# GD32G5x3 register map
File version: 1.0
CPU: CM33 r2p1, little endian, MPU, FPU, 4 interrupt priority bits
Registers are 32-bit, read-write, reset 0x0 unless marked. A register's access mark holds for its fields unless they carry their own. Offsets are from the block's base; [hi:lo] are bit positions.

## DAC0 — Digital-to-analog converter
Base 0x50001000
Same registers: DAC1 0x50001400, DAC2 0x50001800, DAC3 0x50001C00
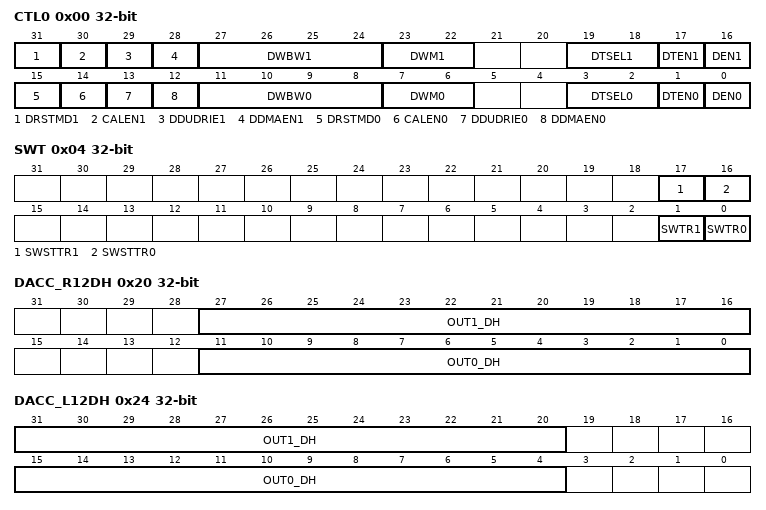
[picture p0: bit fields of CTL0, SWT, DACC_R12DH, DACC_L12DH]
0x00 CTL0 — Control register 0
  [31] DRSTMD1 — DAC_OUT1 reset mode
  [30] CALEN1 — DAC_OUT1 calibration enable
  [29] DDUDRIE1 — DAC_OUT1 DMA underrun interrupt enable
  [28] DDMAEN1 — DAC_OUT1 DMA enable
  [27:24] DWBW1 — DAC_OUT1 noise wave bit width
  [23:22] DWM1 — DAC_OUT1 noise wave mode
  [19:18] DTSEL1 — DAC_OUT1 trigger selection
  [17] DTEN1 — DAC_OUT1 trigger enable
  [16] DEN1 — DAC_OUT1 enable
  [15] DRSTMD0 — DAC_OUT0 reset mode
  [14] CALEN0 — DAC_OUT0 calibration enable
  [13] DDUDRIE0 — DAC_OUT0 DMA underrun interrupt enable
  [12] DDMAEN0 — DAC_OUT0 DMA enable
  [11:8] DWBW0 — DAC_OUT0 noise wave bit width
  [7:6] DWM0 — DAC_OUT0 noise wave mode
  [3:2] DTSEL0 — DAC_OUT0 trigger selection
  [1] DTEN0 — DAC_OUT0 trigger enable
  [0] DEN0 — DAC_OUT0 enable
0x04 SWT wo — Software trigger register
  [17] SWSTTR1 — DAC_OUT1 sawtooth step-up/down software trigger
  [16] SWSTTR0 — DAC_OUT0 sawtooth step-up/down software trigger
  [1] SWTR1 — DAC_OUT1 software trigger, cleared by hardware
  [0] SWTR0 — DAC_OUT0 software trigger, cleared by hardware
0x08 OUT0_R12DH — DAC_OUT0 12-bit right-aligned data holding register
  [11:0] OUT0_DH — DAC_OUT0 12-bit right-aligned data
0x0C OUT0_L12DH — DAC_OUT0 12-bit left-aligned data holding register
  [15:4] OUT0_DH — DAC_OUT0 12-bit left-aligned data
0x10 OUT0_R8DH — DAC_OUT0 8-bit right-aligned data holding register
  [7:0] OUT0_DH — DAC_OUT0 8-bit right-aligned data
0x14 OUT1_R12DH — DAC_OUT1 12-bit right-aligned data holding register
  [11:0] OUT1_DH — DAC_OUT1 12-bit right-aligned data
0x18 OUT1_L12DH — DAC_OUT1 12-bit left-aligned data holding register
  [15:4] OUT1_DH — DAC_OUT1 12-bit left-aligned data
0x1C OUT1_R8DH — DAC_OUT1 8-bit right-aligned data holding register
  [7:0] OUT1_DH — DAC_OUT1 8-bit right-aligned data
0x20 DACC_R12DH — DAC concurrent mode 12-bit right-aligned data holding register
  [27:16] OUT1_DH — DAC_OUT1 12-bit right-aligned data
  [11:0] OUT0_DH — DAC_OUT0 12-bit right-aligned data
0x24 DACC_L12DH — DAC concurrent mode 12-bit left-aligned data holding register
  [31:20] OUT1_DH — DAC_OUT1 12-bit left-aligned data
  [15:4] OUT0_DH — DAC_OUT0 12-bit left-aligned data
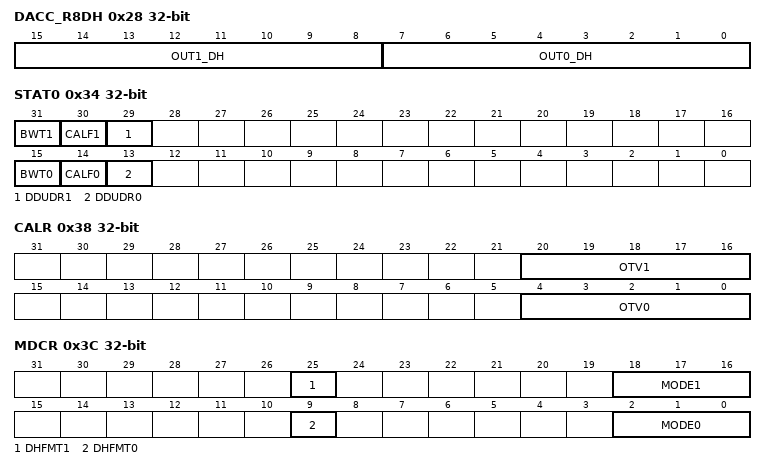
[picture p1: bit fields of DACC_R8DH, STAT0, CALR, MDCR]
0x28 DACC_R8DH — DAC concurrent mode 8-bit right-aligned data holding register
  [15:8] OUT1_DH — DAC_OUT1 8-bit right-aligned data
  [7:0] OUT0_DH — DAC_OUT0 8-bit right-aligned data
0x2C OUT0_DO ro — DAC_OUT0 data output register
  [11:0] OUT0_DO — DAC_OUT0 data output
0x30 OUT1_DO ro — DAC_OUT1 data output register
  [11:0] OUT1_DO — DAC_OUT1 data output
0x34 STAT0 access per field — DAC status register 0
  [31] BWT1 ro — DAC_OUT1 TSAMP1[9:0] writing busy flag
  [30] CALF1 ro — DAC_OUT1 calibration offset flag
  [29] DDUDR1 rw — DAC_OUT1 DMA underrun flag, set by hardware, cleared by software write 1
  [15] BWT0 ro — DAC_OUT0 TSAMP0[9:0] writing busy flag
  [14] CALF0 ro — DAC_OUT0 calibration offset flag
  [13] DDUDR0 rw — DAC_OUT0 DMA underrun flag
0x38 CALR — DAC calibration Register
  [20:16] OTV1 — DAC_OUT1 offset calibration value
  [4:0] OTV0 — DAC_OUT0 offset calibration value
0x3C MDCR — DAC mode control register
  [25] DHFMT1 — DAC_OUT1 data format written in data holding register
  [18:16] MODE1 — DAC_OUT1 mode
  [9] DHFMT0 — DAC_OUT0 data format written in data holding register
  [2:0] MODE0 — DAC_OUT0 mode
0x40 SKSTR0 — DAC sample and keep sample time register 0
  [9:0] TSAMP0 — DAC_OUT0 sample time
0x44 SKSTR1 — DAC sample and keep sample time register 1
  [9:0] TSAMP1 — DAC_OUT1 sample time
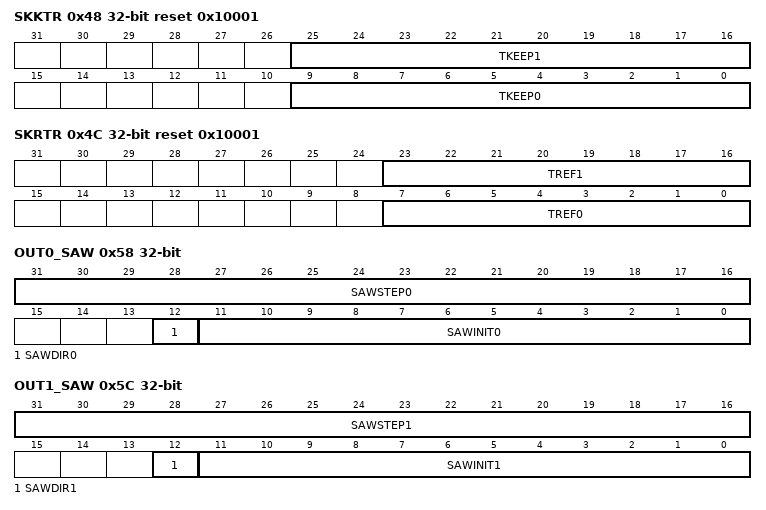
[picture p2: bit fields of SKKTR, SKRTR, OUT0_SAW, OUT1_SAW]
0x48 SKKTR reset 0x10001 — DAC sample and keep keep time register
  [25:16] TKEEP1 — DAC_OUT1 keep time (only available in sample and keep mode)
  [9:0] TKEEP0 — DAC_OUT0 keep time (only available in sample and keep mode)
0x4C SKRTR reset 0x10001 — DAC sample and keep refresh time register
  [23:16] TREF1 — DAC_OUT1 refresh time (only available in sample and keep mode)
  [7:0] TREF0 — DAC_OUT refresh time (only available in sample and keep mode)
0x58 OUT0_SAW — DAC_OUT0 sawtooth register
  [31:16] SAWSTEP0 — DAC_OUT0 sawtooth step value
  [12] SAWDIR0 — DAC_OUT0 sawtooth step direction
  [11:0] SAWINIT0 — DAC_OUT0 sawtooth initial value
0x5C OUT1_SAW — DAC_OUT1 sawtooth register
  [31:16] SAWSTEP1 — DAC_OUT1 sawtooth step value
  [12] SAWDIR1 — DAC_OUT1 sawtooth step direction
  [11:0] SAWINIT1 — DAC_OUT1 sawtooth initial value
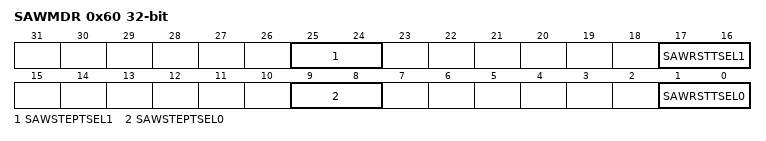
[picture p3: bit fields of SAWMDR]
0x60 SAWMDR — DAC sawtooth mode register
  [25:24] SAWSTEPTSEL1 — DAC_OUT1 sawtooth step-up/down trigger selection
  [17:16] SAWRSTTSEL1 — DAC_OUT1 sawtooth reset to initial value trigger selection
  [9:8] SAWSTEPTSEL0 — DAC_OUT0 sawtooth step-up/down trigger selection
  [1:0] SAWRSTTSEL0 — DAC_OUT0 sawtooth reset to initial value trigger selection
